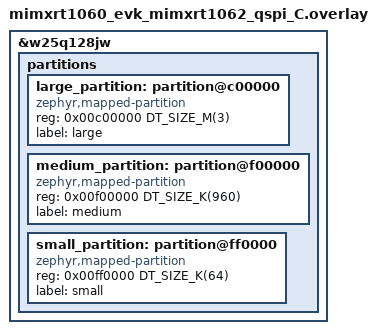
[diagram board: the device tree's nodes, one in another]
/*
 * Copyright 2021,2025 NXP
 *
 * SPDX-License-Identifier: Apache-2.0
 */

/delete-node/ &storage_partition;

&w25q128jw {
	partitions {
		large_partition: partition@c00000 {
			compatible = "zephyr,mapped-partition";
			reg = <0x00c00000 DT_SIZE_M(3)>;
			label = "large";
		};

		medium_partition: partition@f00000 {
			compatible = "zephyr,mapped-partition";
			reg = <0x00f00000 DT_SIZE_K(960)>;
			label = "medium";
		};

		small_partition: partition@ff0000 {
			compatible = "zephyr,mapped-partition";
			reg = <0x00ff0000 DT_SIZE_K(64)>;
			label = "small";
		};
	};
};
